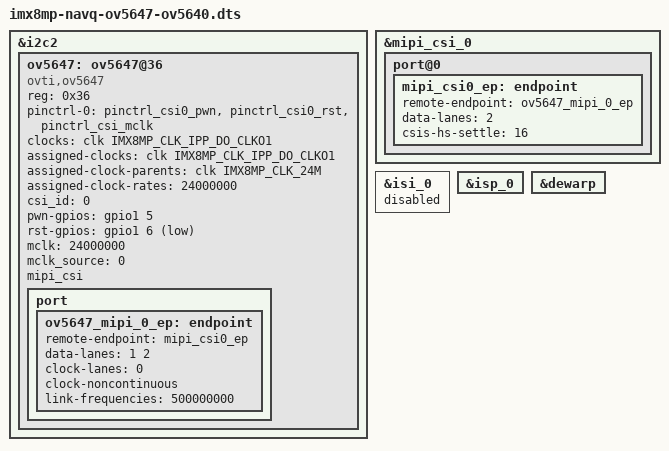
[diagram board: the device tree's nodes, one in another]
#include "imx8mp-navq.dts"

&i2c2 {
	/delete-node/ov5645_mipi@3c;

	ov5647: ov5647@36 {
		compatible = "ovti,ov5647";
		reg = <0x36>;
		pinctrl-names = "default";
		pinctrl-0 = <&pinctrl_csi0_pwn>, <&pinctrl_csi0_rst>, <&pinctrl_csi_mclk>;
		clocks = <&clk IMX8MP_CLK_IPP_DO_CLKO1>;
		clock-names = "xclk";
		assigned-clocks = <&clk IMX8MP_CLK_IPP_DO_CLKO1>;
		assigned-clock-parents = <&clk IMX8MP_CLK_24M>;
		assigned-clock-rates = <24000000>;
		csi_id = <0>;
		pwn-gpios = <&gpio1 5 GPIO_ACTIVE_HIGH>;
		rst-gpios = <&gpio1 6 GPIO_ACTIVE_LOW>;
		mclk = <24000000>;
		mclk_source = <0>;

		mipi_csi;
		status = "okay";
		port {
			ov5647_mipi_0_ep: endpoint {
				remote-endpoint = <&mipi_csi0_ep>;
				data-lanes = <1 2>;
				clock-lanes = <0>;
				clock-noncontinuous;
				link-frequencies = /bits/ 64 <500000000>;
			};
		};
	};
};

&mipi_csi_0 {
	/delete-node/port@0;
	port@0 {
		mipi_csi0_ep: endpoint {
			remote-endpoint = <&ov5647_mipi_0_ep>;
			data-lanes = <2>;
			csis-hs-settle = <16>;
		};
	};
};

&isi_0 {
	status = "disabled";
};

&isp_0 {
	status = "okay";
};

&dewarp {
	status = "okay";
};
